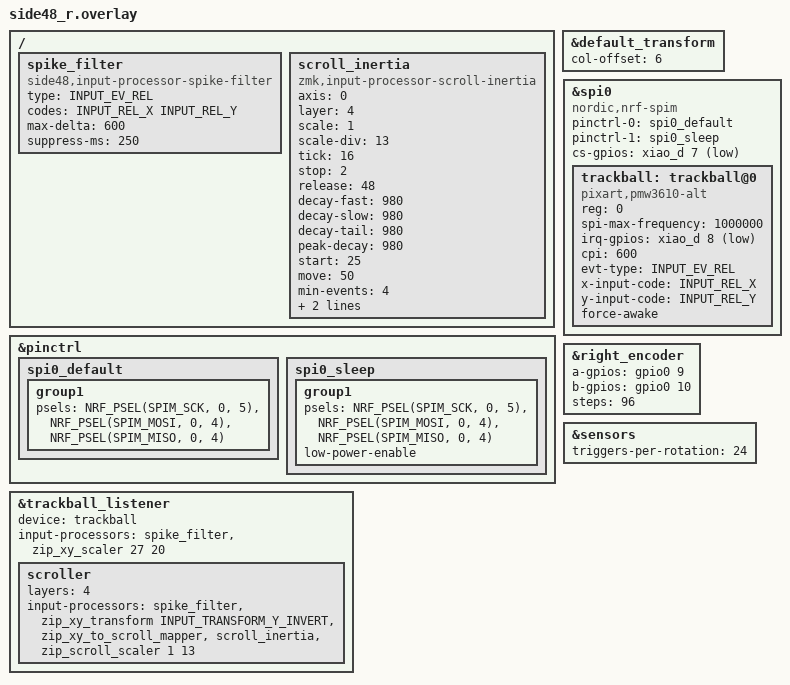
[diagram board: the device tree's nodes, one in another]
#include "side48.dtsi"
#include <input/processors.dtsi>


&default_transform {
    col-offset = <6>;
};


//trackballの設定
&pinctrl {
    spi0_default: spi0_default {    //通常動作時
        group1 {
            psels = <NRF_PSEL(SPIM_SCK,  0, 5)>,    //P0.05(SCLK)
                    <NRF_PSEL(SPIM_MOSI, 0, 4)>,    //P0.04(SDIO(MOSI,MISO兼用))
                    <NRF_PSEL(SPIM_MISO, 0, 4)>;
        };
    };

    spi0_sleep: spi0_sleep {        //スリープ時
        group1 {
            psels = <NRF_PSEL(SPIM_SCK,  0, 5)>,
                    <NRF_PSEL(SPIM_MOSI, 0, 4)>,
                    <NRF_PSEL(SPIM_MISO, 0, 4)>;
            low-power-enable;
        };
    };
};

&spi0 {
    status = "okay";
    compatible = "nordic,nrf-spim";
    pinctrl-0 = <&spi0_default>;
    pinctrl-1 = <&spi0_sleep>;
    pinctrl-names = "default", "sleep";
    cs-gpios = <&xiao_d 7 GPIO_ACTIVE_LOW>;  //P1.12(CS)

    trackball: trackball@0 {
        status = "okay";
        compatible = "pixart,pmw3610-alt";
        reg = <0>;
        spi-max-frequency = <1000000>;
        irq-gpios = <&xiao_d 8 (GPIO_ACTIVE_LOW | GPIO_PULL_UP)>; //P1.13(MOTION)
        cpi = <600>;
        evt-type = <INPUT_EV_REL>;
        x-input-code = <INPUT_REL_X>;
        y-input-code = <INPUT_REL_Y>;
        force-awake;
    };
};

/ {
    // LiTom と同じスパイク除去フィルタ。センサーが省電力から復帰した直後に
    // 届く壊れた移動量 (最大 1500 超、符号ばらばら) を捨てる。
    // スケーリングより前 (生のカウントのまま) に置くこと。
    spike_filter: spike_filter {
        compatible = "side48,input-processor-spike-filter";
        #input-processor-cells = <0>;
        type = <INPUT_EV_REL>;
        codes = <INPUT_REL_X INPUT_REL_Y>;
        max-delta = <600>;
        suppress-ms = <250>;
    };

    // 慣性スクロール (iOS風): 玉を弾いて離すとスクロールが減衰しながら続く。
    // 値は LiTom_R.overlay と同一 (センサー送信間隔 16ms 前提)。
    // 慣性出力は下流のプロセッサをバイパスするため、scale / scale-div は
    // 下流の &zip_scroll_scaler の引数 (1 / 13) と一致させること。
    scroll_inertia: scroll_inertia {
        compatible = "zmk,input-processor-scroll-inertia";
        #input-processor-cells = <0>;
        axis = <0>;           // 縦横フリー
        layer = <4>;          // スクロールレイヤー (T 長押し)
        scale = <1>;
        scale-div = <13>;
        tick = <16>;
        stop = <2>;
        release = <48>;
        decay-fast = <980>;
        decay-slow = <980>;
        decay-tail = <980>;
        peak-decay = <980>;
        start = <25>;
        move = <50>;
        min-events = <4>;
        friction = <30>;
        suppress-limit = <25>;
    };
};

// Overrides for the input listener node
&trackball_listener {
    status = "okay";
    device = <&trackball>;
    // カーソル: LiTom (600cpi x Studio 倍率 1.35) に合わせて 27/20 倍。
    // &spike_filter は必ず先頭。
    input-processors =
            <&spike_filter>,
            <&zip_xy_scaler 27 20>;

    // レイヤー4 (T 長押し) ではトラックボールをスクロールとして扱う。
    // 並びは LiTom と同じ: Y反転 -> スクロール化 -> 慣性 -> 1/13 縮小。
    scroller {
        layers = <4>;
        input-processors =
                <&spike_filter>,
                <&zip_xy_transform INPUT_TRANSFORM_Y_INVERT>,
                <&zip_xy_to_scroll_mapper>,
                <&scroll_inertia>,
                <&zip_scroll_scaler 1 13>;
    };
};


//encoderの設定
&right_encoder{
    a-gpios = <&gpio0  9 (GPIO_ACTIVE_HIGH | GPIO_PULL_UP)>;
    b-gpios = <&gpio0 10 (GPIO_ACTIVE_HIGH | GPIO_PULL_UP)>;
    steps = <96>;
    status = "okay";
};

&sensors {
   triggers-per-rotation = <24>;
};

